# rtcss_RTC_2B1F0000h register map
Vendor: Texas Instruments
Peripheral module from a debugger description file (folder AM275x).
Registers are 32-bit, read-write, reset 0x0 unless marked. A register's access mark holds for its fields unless they carry their own. Offsets are as the file gives them; lines under a group give offsets from that group; [hi:lo] are bit positions; {n}, {i} and the like mark numbered series; 'fields as' and 'values as' point back to an identical list; <NAME> marks a mode.

## RTC
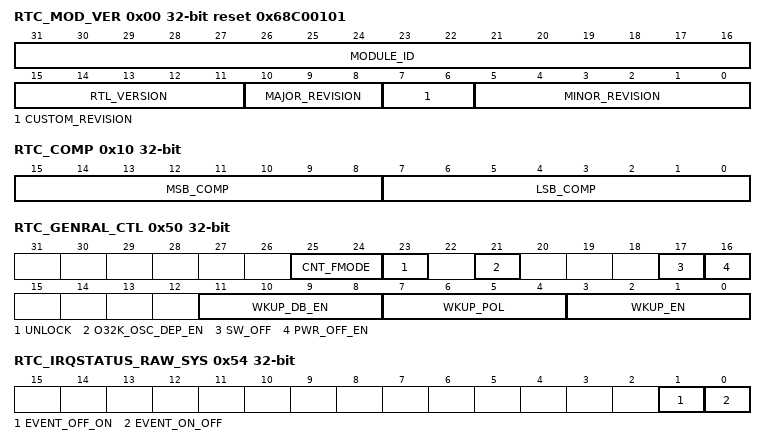
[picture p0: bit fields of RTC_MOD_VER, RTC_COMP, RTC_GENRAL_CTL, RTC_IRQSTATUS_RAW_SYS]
0x00 RTC_MOD_VER ro reset 0x68C00101 — The Module and Version Register identifies the module identifier and revision of the RTC module.
  [31:16] MODULE_ID — RTC module ID.
  [15:11] RTL_VERSION
  [10:8] MAJOR_REVISION
  [7:6] CUSTOM_REVISION
  [5:0] MINOR_REVISION
0x04 RTC_SUB_S_CNT — This register counts the 32768 Hz clock events
  [14:0] SUB_S_CNT — This counts the 32768 Hz clock events to achive 1 sec event for the sec counter, rollvers after 0x7fff or 1 Sec running on 32768Hz
0x08 RTC_S_CNT_LSW — The lower word of the seconds counter
  [31:0] S_CNT_LSW — This counts the 1 sec events, it is the lower 32 bits of the 48 bit counter, 1 = 1 Seconds, 2 = 2 Seconds, N = N Seconds
0x0C RTC_S_CNT_MSW — The upper word of the seconds counter
  [15:0] S_CNT_MSW — This counts the 1 sec events, it is the upper 16 bits of the 48 bit counter
0x10 RTC_COMP — This register used to program the value of the 32768 periods to be added to the 32768 counter every 4096 Secs. This is used to compensate the oscillator drift.
  [15:8] MSB_COMP — Indicates number of 32-kHz periods to be added into the 32-kHz counter every 4096 Secs, twos complement That means that to add one 32-kHz oscillator period every hour, the SW must write FFFF into COMP_MSB and COMP_LSB. To remove one 32-kHz oscillator period every hour, the SW must write 0001 into RTC_COMP_MSB and RTC_COMP_LSB. The 7FFF value is forbidden.
  [7:0] LSB_COMP — Indicates number of 32-kHz periods to be added into the 32-kHz counter every 4096 Secs, twos complement That means that to add one 32-kHz oscillator period every hour, the SW must write FFFF into COMP_MSB and COMP_LSB. To remove one 32-kHz oscillator period every hour, the SW must write 0001 into RTC_COMP_MSB and RTC_COMP_LSB. The 7FFF value is forbidden.
0x18 RTC_OFF_ON_S_CNT_LSW reset 0x1 — This register defines the OFF to ON time event
  [31:0] OFF_ON_S_CNT_LSW — The lower word of the OFF to ON time
0x1C RTC_OFF_ON_S_CNT_MSW reset 0x8000 — This register defines the OFF to ON time event
  [15:0] OFF_ON_S_CNT_MSW — The
0x20 RTC_ON_OFF_S_CNT_LSW reset 0x1 — This register defines the ON to OFF time event
  [31:0] ON_OFF_S_CNT_LSW — The
0x24 RTC_ON_OFF_S_CNT_MSW reset 0x8000 — This register defines the ON to OFF time event
  [15:0] ON_OFF_S_CNT_MSW — The
0x28 RTC_DEBOUNCE — The Debounce register defines the debounce timer useing the 32768 Hz clock. It allows choosing the timing or the accuracy of
  [7:0] DEBOUNCE — Debounce time 0 debounce time is 30.52 uS N debounce time is 30.52us*(N+1)
0x2C RTC_ANALOG — This register goes to the Analog Block
  [31:0] ANALOG — Analog Configuration MMR
0x30 RTC_SCRATCH0_j — The Scratch Storage Registers can be used to hold information in the battery backuped domain while the device is powered down.
  [31:0] SCRATCH0 — The scratch0 holds data in the battery backed domain for use by the device when powered on. This would typically be used to store signatures other information of similar ilk.
0x50 RTC_GENRAL_CTL access per field — This is the main RTC control register
  [25:24] CNT_FMODE rw — This defines which read freeze mode is enabled, 10 = S_CNT_LSW When SW reads S_CNT_LSW it will snap S_CNT_MSW 01 = SUB_S_CNT When SW reads SUB_S_CNT it will snap S_CNT_MSW and S_CNT_LSW 00 = Disable
  [23] UNLOCK ro — The status of the UNLOCKED state, 1 = UnLocked 0 = Locked
  [21] O32K_OSC_DEP_EN rw — This controls if a high to low transition dependence is required before the CORE domain can read or write the ON domain, 1 = Enable 0 = Disable
  [17] SW_OFF wo — The SW can issue a ON_OFF event, Wrt 1 for OFF event Wrt 0 has no effect, The OFF event will occur within 31uS and relock the core
  [16] PWR_OFF_EN rw — This allows the PMIC_ENABLE to go from a ON to OFF state by SW or ON_OFF event
  [11:8] WKUP_DB_EN rw — External Wakeup Debounce Enable 1 = Enable 0 = Disable
  [7:4] WKUP_POL rw — External Wakeup Polarity 1 = Active High = Active Low
  [3:0] WKUP_EN rw — External Wakeup Enable 1 = Enable 0 = Disable
0x54 RTC_IRQSTATUS_RAW_SYS access not given
  [1] EVENT_OFF_ON — Raw status of OFF_ON interrupt for event_off_on. Write 1 to set the (raw) status, mostly for debug. Writing a 0 has no effect. (access R/W1TS)
  [0] EVENT_ON_OFF — Raw status of ON_OFF interrupt for event_on_off. Write 1 to set the (raw) status, mostly for debug. Writing a 0 has no effect. (access R/W1TS)
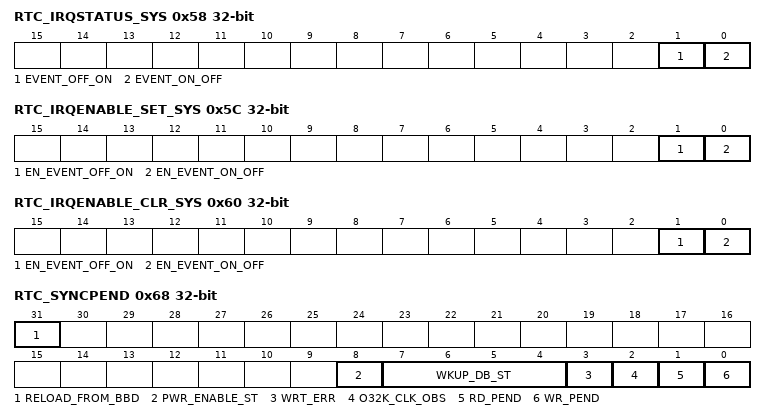
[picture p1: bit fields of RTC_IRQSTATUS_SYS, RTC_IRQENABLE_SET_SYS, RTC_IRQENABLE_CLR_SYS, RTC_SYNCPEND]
0x58 RTC_IRQSTATUS_SYS access not given — The EXT_WAKEUP events are level-sensitive and not edge-sensitive. When debounce is enabled, clearing an EXT_WAKEUP event may have no effect because the interrupt triggers again immediately. See the Interrupt Service Routine section of the Programming Usage Guide.
  [1] EVENT_OFF_ON — Enabled status of OFF_ON interrupt for event_off_on. Write 1 to clear the status after interrupt has been serviced (raw status gets cleared, i.e. even if not enabled). Writing a 0 has no effect. (access R/W1TC)
  [0] EVENT_ON_OFF — Enabled status of ON_OFF interrupt for event_on_off. Write 1 to clear the status after interrupt has been serviced (raw status gets cleared, i.e. even if not enabled). Writing a 0 has no effect. (access R/W1TC)
0x5C RTC_IRQENABLE_SET_SYS access not given
  [1] EN_EVENT_OFF_ON — Enable set for OFF_ON interrupt for event_off_on. Writing a 1 will enable the interrupt, and set this bit as well as the corresponding Interrupt Enable Clear Register. Writing a 0 has no effect. (access R/W1TS)
  [0] EN_EVENT_ON_OFF — Enable set for ON_OFF interrupt for event_on_off. Writing a 1 will enable the interrupt, and set this bit as well as the corresponding Interrupt Enable Clear Register. Writing a 0 has no effect. (access R/W1TS)
0x60 RTC_IRQENABLE_CLR_SYS access not given
  [1] EN_EVENT_OFF_ON — Enable clear for OFF_ON interrupt for event_off_on. Writing a 1 will disable the interrupt, and clear this bit as well as the corresponding Interrupt Enable Set Register. Writing a 0 has no effect. (access R/W1TC)
  [0] EN_EVENT_ON_OFF — Enable clear for ON_OFF interrupt for event_on_off. Writing a 1 will disable the interrupt, and clear this bit as well as the corresponding Interrupt Enable Set Register. Writing a 0 has no effect. (access R/W1TC)
0x68 RTC_SYNCPEND access not given — The SW can determine status of wrt and rd access along with other status from the ON domain This register is located in the CORE domain and provides the control and status of the MMR Sync state machine. The RELOAD_FROM_BBD bit directly controls the the MMR Sync state machine in the DIG_CORE domain and ignores the Functional Protection state machine. The RELOAD_FROM_BBD bit can be written with 1 regardless of if RTC is locked or unlocked. RTC will ignore a write of 1 to the RELOAD_FROM_BBD bit if RTC_SYNCPEND.RD_PEND is 1, or if RTC_SYNCPEND.WR_PEND is 1, or if any interrupt status bit in the RTC_IRQSTATUS_RAW_SYS register is 1.
  [31] RELOAD_FROM_BBD rw — The reload_from_bbd allows the registers to be reloaded from the battery backed domain. This is only allowed when the battery backed domain interface state machine is idle.Writing 1 triggers the MMR Sync to read the registers from the battery backed domain. This requires RD_PEND, WR_PEND, and all interrupts' raw status to be 0 when this is written. This operation affects the RD_PEND bit.
  [8] PWR_ENABLE_ST ro — The SW can read the state of PIMIC_ENABLE pin, this is raw state
  [7:4] WKUP_DB_ST ro — The SW can read the state of EXT_WAKEUP pins, this is raw state
  [3] WRT_ERR — Write Error ConditionWrt 1 to ClrSet when SW tries to Wrt when RTL is LOCKED or Wrt when RD_PEND is set 0 Not Occurred1 Occurred (access R/W1TC)
  [2] O32K_CLK_OBS ro — The SW can read the state of the main 32k clock
  [1] RD_PEND rw — Status of synchronization from ON Domain after CORE reset or RELOAD_FROM_BBD 0 Completed1 Pending or active
  [0] WR_PEND rw — Status of synchronization to ON Domain after writing to CORE Domain over VBUS 0 Completed1 Pending or active
0x70 RTC_KICK0 wo — The written data must be 0x83e70b13 to unlock this register. It must be written before the Kick1 register. The normal procedure to re-lock the functional protection mechanism is to write 0 to this register.
  [31:0] KICK0 — Kick0 MMR, must write 0x83e70b13 to unlock this register
0x74 RTC_KICK1 wo — The Kick1 register allows writing to unlock the kick1 data and the kicker mechanism to write to other MMRs. The written data must be 0x95a4f1e0 to unlock this register. If this is unlocked after the kick0 register is unlocked then the kicker mechanism is unlockedThe HOST must ensure that there is at least 60 microseconds of delay between a 'new' lock state to a 'new' unlock state. This should be implemented by ensuring that RTC_SYNCPEND.WR_PEND is 0 before performing the unlock writes. This is a consequence of the limitation that the functional unlock sequence must not be written while the mechanism is unlocked; if the unlock sequence is written at the wrong time, then the core domain and battery domain will not agree about their unlocked status. This will not be diagnosable in software and there is no recommended error recovery sequence for this condition.For No Analog support, leave it unlocked.
  [31:0] KICK1 — Kick1 MMR, must write 0x95a4f1e0 to unlock this register and the other MMRs
